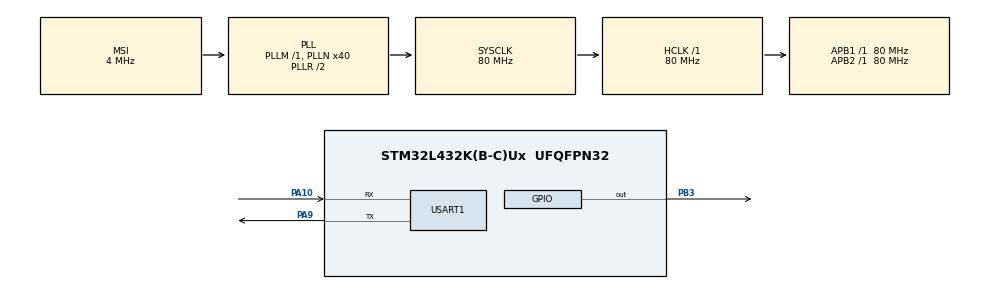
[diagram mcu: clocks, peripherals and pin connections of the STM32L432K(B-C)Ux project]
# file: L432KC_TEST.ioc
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Mcu.Family=STM32L4
Mcu.Name=STM32L432K(B-C)Ux
Mcu.Package=UFQFPN32
NVIC.PriorityGroup=NVIC_PRIORITYGROUP_4
PA0.Mode=HSE-External-Clock-Source-for-LittleOrca
PA0.Signal=RCC_CK_IN
PA10.Mode=Asynchronous
PA10.Signal=USART1_RX
PA9.Mode=Asynchronous
PA9.Signal=USART1_TX
PB3\ (JTDO-TRACESWO).Signal=GPIO_Output
ProjectManager.HeapSize=0x200
ProjectManager.StackSize=0x400
ProjectManager.TargetToolchain=MDK-ARM V5.32
RCC.ADCFreq_Value=16000000
RCC.AHBFreq_Value=80000000
RCC.APB1Freq_Value=80000000
RCC.APB1TimFreq_Value=80000000
RCC.APB2Freq_Value=80000000
RCC.APB2TimFreq_Value=80000000
RCC.CortexFreq_Value=80000000
RCC.HCLKFreq_Value=80000000
RCC.HSE_VALUE=8000000
RCC.HSI48_VALUE=48000000
RCC.HSI_VALUE=16000000
RCC.MSI_VALUE=4000000
RCC.PLLN=40
RCC.SYSCLKFreq_VALUE=80000000
RCC.SYSCLKSource=RCC_SYSCLKSOURCE_PLLCLK
RCC.USBFreq_Value=16000000
RCC.VCOOutputFreq_Value=160000000
USART1.VirtualMode-Asynchronous=VM_ASYNC
board=custom

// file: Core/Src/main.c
/* USER CODE BEGIN Header */
/**
  ******************************************************************************
  * @file           : main.c
  * @brief          : Main program body
  ******************************************************************************
  * @attention
  *
  * <h2><center>&copy; Copyright (c) 2022 STMicroelectronics.
  * All rights reserved.</center></h2>
  *
  * This software component is licensed by ST under BSD 3-Clause license,
  * the "License"; You may not use this file except in compliance with the
  * License. You may obtain a copy of the License at:
  *                        opensource.org/licenses/BSD-3-Clause
  *
  ******************************************************************************
  */
/* USER CODE END Header */
#include "main.h"
#include "usart.h"
#include "gpio.h"

void SystemClock_Config(void);

int main(void)
{

  /* MCU Configuration--------------------------------------------------------*/

  /* Reset of all peripherals, Initializes the Flash interface and the Systick. */
  HAL_Init();

  /* Configure the system clock */
  SystemClock_Config();

  /* Initialize all configured peripherals */
  MX_GPIO_Init();
  MX_USART1_UART_Init();

  /* Infinite loop */
  /* USER CODE BEGIN WHILE */
	uint8_t str[] = "Hello World!\n\r";

  while (1)
  {

		HAL_GPIO_WritePin(GPIOB, GPIO_PIN_3, GPIO_PIN_SET);
		HAL_UART_Transmit(&huart1, str, 15, 10);
	  HAL_Delay(500);
	  HAL_GPIO_WritePin(GPIOB, GPIO_PIN_3, GPIO_PIN_RESET);
		//HAL_UART_Transmit(&huart1, str, 15, 10);
	  HAL_Delay(500);
    /* USER CODE END WHILE */

  }
}

void SystemClock_Config(void)
{
  RCC_OscInitTypeDef RCC_OscInitStruct = {0};
  RCC_ClkInitTypeDef RCC_ClkInitStruct = {0};

  /** Configure the main internal regulator output voltage
  */
  if (HAL_PWREx_ControlVoltageScaling(PWR_REGULATOR_VOLTAGE_SCALE1) != HAL_OK)
  {
    Error_Handler();
  }
  /** Initializes the RCC Oscillators according to the specified parameters
  * in the RCC_OscInitTypeDef structure.
  */
  RCC_OscInitStruct.OscillatorType = RCC_OSCILLATORTYPE_MSI;
  RCC_OscInitStruct.MSIState = RCC_MSI_ON;
  RCC_OscInitStruct.MSICalibrationValue = 0;
  RCC_OscInitStruct.MSIClockRange = RCC_MSIRANGE_6;
  RCC_OscInitStruct.PLL.PLLState = RCC_PLL_ON;
  RCC_OscInitStruct.PLL.PLLSource = RCC_PLLSOURCE_MSI;
  RCC_OscInitStruct.PLL.PLLM = 1;
  RCC_OscInitStruct.PLL.PLLN = 40;
  RCC_OscInitStruct.PLL.PLLP = RCC_PLLP_DIV7;
  RCC_OscInitStruct.PLL.PLLQ = RCC_PLLQ_DIV2;
  RCC_OscInitStruct.PLL.PLLR = RCC_PLLR_DIV2;
  if (HAL_RCC_OscConfig(&RCC_OscInitStruct) != HAL_OK)
  {
    Error_Handler();
  }
  /** Initializes the CPU, AHB and APB buses clocks
  */
  RCC_ClkInitStruct.ClockType = RCC_CLOCKTYPE_HCLK|RCC_CLOCKTYPE_SYSCLK
                              |RCC_CLOCKTYPE_PCLK1|RCC_CLOCKTYPE_PCLK2;
  RCC_ClkInitStruct.SYSCLKSource = RCC_SYSCLKSOURCE_PLLCLK;
  RCC_ClkInitStruct.AHBCLKDivider = RCC_SYSCLK_DIV1;
  RCC_ClkInitStruct.APB1CLKDivider = RCC_HCLK_DIV1;
  RCC_ClkInitStruct.APB2CLKDivider = RCC_HCLK_DIV1;

  if (HAL_RCC_ClockConfig(&RCC_ClkInitStruct, FLASH_LATENCY_4) != HAL_OK)
  {
    Error_Handler();
  }
}

void Error_Handler(void)
{
  __disable_irq();
  while (1)
  {
  }
}
